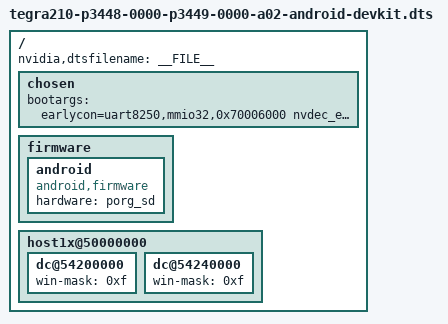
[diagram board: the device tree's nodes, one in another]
#include "tegra210-p3448-0000-p3449-0000-a02.dts"
#include "porg-platforms/tegra210-porg-comms.dtsi"

/ {
	nvidia,dtsfilename = __FILE__;

	chosen {
		bootargs = "earlycon=uart8250,mmio32,0x70006000 nvdec_enabled=0";
	};

	firmware {
		android {
			compatible = "android,firmware";
			hardware = "porg_sd";
		};
	};

	host1x@50000000 {
		dc@54200000 {
			win-mask = <0xf>;
		};

		dc@54240000 {
			win-mask = <0xf>;
		};
	};
};
